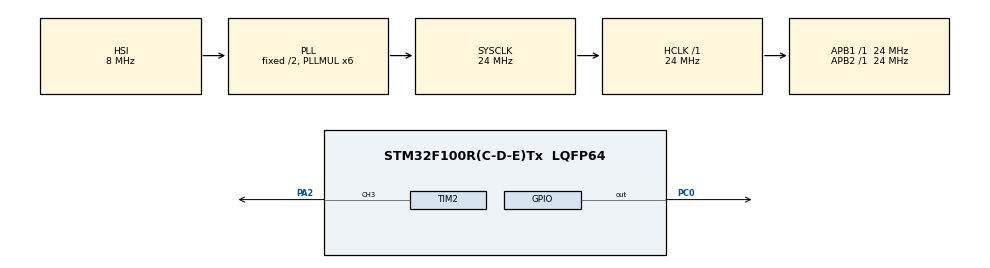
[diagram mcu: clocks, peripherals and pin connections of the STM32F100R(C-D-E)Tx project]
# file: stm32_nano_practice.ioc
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Mcu.Family=STM32F1
Mcu.Name=STM32F100R(C-D-E)Tx
Mcu.Package=LQFP64
NVIC.PriorityGroup=NVIC_PRIORITYGROUP_4
NVIC.TIM2_IRQn=true\:0\:0\:false\:false\:true\:true\:true
PA13.Mode=Serial_Wire
PA13.Signal=SYS_JTMS-SWDIO
PA14.Mode=Serial_Wire
PA14.Signal=SYS_JTCK-SWCLK
PA2.Signal=S_TIM2_CH3
PC0.GPIO_Speed=GPIO_SPEED_FREQ_HIGH
PC0.PinState=GPIO_PIN_SET
PC0.Signal=GPIO_Output
PC14-OSC32_IN.Mode=LSE-External-Oscillator
PC14-OSC32_IN.Signal=RCC_OSC32_IN
PC15-OSC32_OUT.Mode=LSE-External-Oscillator
PC15-OSC32_OUT.Signal=RCC_OSC32_OUT
PD0-OSC_IN.Mode=HSE-External-Oscillator
PD0-OSC_IN.Signal=RCC_OSC_IN
PD1-OSC_OUT.Mode=HSE-External-Oscillator
PD1-OSC_OUT.Signal=RCC_OSC_OUT
ProjectManager.HeapSize=0x200
ProjectManager.StackSize=0x400
ProjectManager.TargetToolchain=MDK-ARM V5.27
RCC.AHBFreq_Value=24000000
RCC.APB1Freq_Value=24000000
RCC.APB1TimFreq_Value=24000000
RCC.APB2Freq_Value=24000000
RCC.APB2TimFreq_Value=24000000
RCC.HCLKFreq_Value=24000000
RCC.PLLMUL=RCC_PLL_MUL6
RCC.SYSCLKFreq_VALUE=24000000
RCC.SYSCLKSource=RCC_SYSCLKSOURCE_PLLCLK
SH.S_TIM2_CH3.0=TIM2_CH3,PWM Generation3 CH3
TIM2.Channel-PWM\ Generation3\ CH3=TIM_CHANNEL_3
TIM2.Period=10000
TIM2.Prescaler=5
VP_TIM2_VS_ClockSourceINT.Mode=Internal
board=custom

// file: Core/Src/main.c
/* USER CODE BEGIN Header */
/**
  ******************************************************************************
  * @file           : main.c
  * @brief          : Main program body
  ******************************************************************************
  * @attention
  *
  * <h2><center>&copy; Copyright (c) 2021 STMicroelectronics.
  * All rights reserved.</center></h2>
  *
  * This software component is licensed by ST under BSD 3-Clause license,
  * the "License"; You may not use this file except in compliance with the
  * License. You may obtain a copy of the License at:
  *                        opensource.org/licenses/BSD-3-Clause
  *
  ******************************************************************************
  */
/* USER CODE END Header */
#include "main.h"

TIM_HandleTypeDef htim2;

/* USER CODE BEGIN PV */

uint16_t PWM_value;								// PWM value to be given
uint16_t PWM_init      = 1000*4;  // Intialisation
uint16_t PWM_PREFLIGHT = 1250*4;
uint16_t PWM					 = 1190*4;
uint16_t PWM_start     = 1300*4;  // PWM starting value for sync loss/ start up test
uint16_t PWM_End       = 1500*4;	// End value of PWM for sync loss/ start up test
uint16_t PWM_Slew_up   = 25*4;		// Slew rate for ramping up
uint16_t PWM_Slew_down = 25*4;		// Slew rate for ramping down
uint16_t Ramp_up   = 0;
uint16_t Ramp_down = 0;
uint16_t Ramp_init = 0;

/* USER CODE END PV */

void SystemClock_Config(void);
static void MX_GPIO_Init(void);
static void MX_TIM2_Init(void);

/* USER CODE BEGIN 0 */
void HAL_TIM_PeriodElapsedCallback(TIM_HandleTypeDef*htim)
{
	if(htim->Instance==TIM2)
	{
		HAL_GPIO_TogglePin(GPIOC, GPIO_PIN_0);
	}
}
/* USER CODE END 0 */

int main(void)
{
  /* USER CODE BEGIN 1 */
		PWM_value = PWM_init;
  /* USER CODE END 1 */

  /* MCU Configuration--------------------------------------------------------*/

  /* Reset of all peripherals, Initializes the Flash interface and the Systick. */
  HAL_Init();

  /* Configure the system clock */
  SystemClock_Config();

  /* Initialize all configured peripherals */
  MX_GPIO_Init();
  MX_TIM2_Init();
	HAL_TIM_PWM_Start_IT(&htim2, TIM_CHANNEL_3);
  /* USER CODE BEGIN 2 */
//	HAL_TIM_PWM_Start_IT(&htim2, TIM_CHANNEL_3);

	htim2.Instance->CCR3 = PWM_init;
	HAL_Delay(3000);
  /* USER CODE END 2 */

  /* Debugger INPUT*/
#if MANUAL_PWM

	PWM_value = PWM_init/4;
	while(1)
	{
		HAL_Delay(1000);
		htim2.Instance->CCR3= PWM_value*4;
	}
#endif

	htim2.Instance->CCR3 = PWM;
	HAL_Delay(5000);
	htim2.Instance->CCR3 = PWM_PREFLIGHT;
	HAL_Delay(5000);
	Ramp_init = 1;
	Ramp_up = 1;

  while (1)
  {

  }
}

void SystemClock_Config(void)
{
  RCC_OscInitTypeDef RCC_OscInitStruct = {0};
  RCC_ClkInitTypeDef RCC_ClkInitStruct = {0};

  /** Initializes the RCC Oscillators according to the specified parameters
  * in the RCC_OscInitTypeDef structure.
  */
  RCC_OscInitStruct.OscillatorType = RCC_OSCILLATORTYPE_HSI;
  RCC_OscInitStruct.HSIState = RCC_HSI_ON;
  RCC_OscInitStruct.HSICalibrationValue = RCC_HSICALIBRATION_DEFAULT;
  RCC_OscInitStruct.PLL.PLLState = RCC_PLL_ON;
  RCC_OscInitStruct.PLL.PLLSource = RCC_PLLSOURCE_HSI_DIV2;
  RCC_OscInitStruct.PLL.PLLMUL = RCC_PLL_MUL6;
  if (HAL_RCC_OscConfig(&RCC_OscInitStruct) != HAL_OK)
  {
    Error_Handler();
  }
  /** Initializes the CPU, AHB and APB buses clocks
  */
  RCC_ClkInitStruct.ClockType = RCC_CLOCKTYPE_HCLK|RCC_CLOCKTYPE_SYSCLK
                              |RCC_CLOCKTYPE_PCLK1|RCC_CLOCKTYPE_PCLK2;
  RCC_ClkInitStruct.SYSCLKSource = RCC_SYSCLKSOURCE_PLLCLK;
  RCC_ClkInitStruct.AHBCLKDivider = RCC_SYSCLK_DIV1;
  RCC_ClkInitStruct.APB1CLKDivider = RCC_HCLK_DIV1;
  RCC_ClkInitStruct.APB2CLKDivider = RCC_HCLK_DIV1;

  if (HAL_RCC_ClockConfig(&RCC_ClkInitStruct, FLASH_LATENCY_0) != HAL_OK)
  {
    Error_Handler();
  }
}

static void MX_TIM2_Init(void)
{

  TIM_ClockConfigTypeDef sClockSourceConfig = {0};
  TIM_MasterConfigTypeDef sMasterConfig = {0};
  TIM_OC_InitTypeDef sConfigOC = {0};

  htim2.Instance = TIM2;
  htim2.Init.Prescaler = 5;
  htim2.Init.CounterMode = TIM_COUNTERMODE_UP;
  htim2.Init.Period = 10000;
  htim2.Init.ClockDivision = TIM_CLOCKDIVISION_DIV1;
  htim2.Init.AutoReloadPreload = TIM_AUTORELOAD_PRELOAD_DISABLE;
  if (HAL_TIM_Base_Init(&htim2) != HAL_OK)
  {
    Error_Handler();
  }
  sClockSourceConfig.ClockSource = TIM_CLOCKSOURCE_INTERNAL;
  if (HAL_TIM_ConfigClockSource(&htim2, &sClockSourceConfig) != HAL_OK)
  {
    Error_Handler();
  }
  if (HAL_TIM_PWM_Init(&htim2) != HAL_OK)
  {
    Error_Handler();
  }
  sMasterConfig.MasterOutputTrigger = TIM_TRGO_RESET;
  sMasterConfig.MasterSlaveMode = TIM_MASTERSLAVEMODE_DISABLE;
  if (HAL_TIMEx_MasterConfigSynchronization(&htim2, &sMasterConfig) != HAL_OK)
  {
    Error_Handler();
  }
  sConfigOC.OCMode = TIM_OCMODE_PWM1;
  sConfigOC.Pulse = 0;
  sConfigOC.OCPolarity = TIM_OCPOLARITY_HIGH;
  sConfigOC.OCFastMode = TIM_OCFAST_DISABLE;
  if (HAL_TIM_PWM_ConfigChannel(&htim2, &sConfigOC, TIM_CHANNEL_3) != HAL_OK)
  {
    Error_Handler();
  }
  HAL_TIM_MspPostInit(&htim2);

}

static void MX_GPIO_Init(void)
{
  GPIO_InitTypeDef GPIO_InitStruct = {0};

  /* GPIO Ports Clock Enable */
  __HAL_RCC_GPIOC_CLK_ENABLE();
  __HAL_RCC_GPIOD_CLK_ENABLE();
  __HAL_RCC_GPIOA_CLK_ENABLE();

  /*Configure GPIO pin Output Level */
  HAL_GPIO_WritePin(GPIOC, GPIO_PIN_0, GPIO_PIN_SET);

  /*Configure GPIO pin : PC0 */
  GPIO_InitStruct.Pin = GPIO_PIN_0;
  GPIO_InitStruct.Mode = GPIO_MODE_OUTPUT_PP;
  GPIO_InitStruct.Pull = GPIO_NOPULL;
  GPIO_InitStruct.Speed = GPIO_SPEED_FREQ_HIGH;
  HAL_GPIO_Init(GPIOC, &GPIO_InitStruct);

}

/* USER CODE BEGIN 4 */
uint16_t count1=0,count2=0;
void HAL_TIM_PWM_PulseFinishedCallback(TIM_HandleTypeDef *htim)
	{
		if( Ramp_init == 1)
		{
			if( Ramp_up == 1)
			{
				PWM_value = PWM_start;
				count1++;
				if(count1>320)
				{
					Ramp_up = 0;
					count1 = 0;
					//Ramp_down = 1;
				}
				if ( Ramp_up == 0)
				{
					if(PWM_value < PWM_End)
					{
						PWM_value = PWM_value + PWM_Slew_up;
						Ramp_down = 1;
					}
					else
					{
						Ramp_down = 1;
					}
				}
			}
			else if (Ramp_down == 1)
			{
				PWM_value = PWM_End;
				count2++;
				if(count2>320)
				{
					Ramp_down = 0;
					count2 = 0;
				}
			 if(Ramp_down == 0)
				{
					if(PWM_value>PWM_start)
					{
						PWM_value = PWM_value - PWM_Slew_down;
						Ramp_up = 1;
					}
					else
					{
						Ramp_up = 1;
					}
				}
			}
			htim2.Instance->CCR3 = PWM_value;
		}
	}
/* USER CODE END 4 */

void Error_Handler(void)
{
}

/************************ (C) COPYRIGHT STMicroelectronics *****END OF FILE****/
